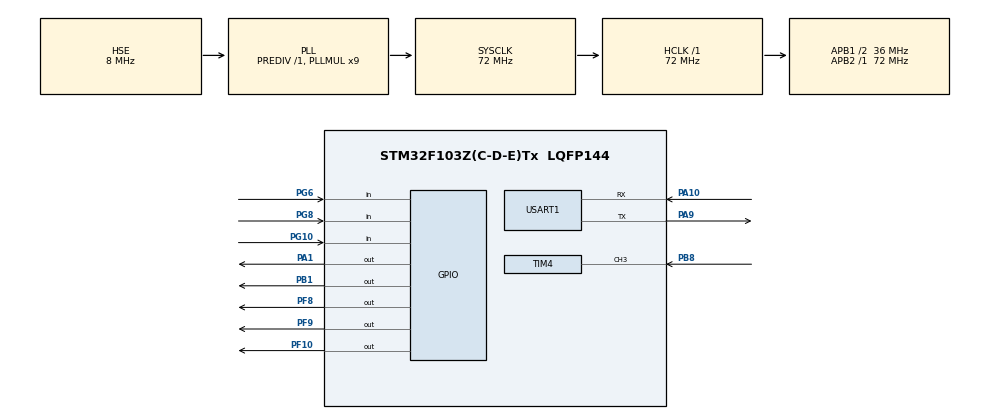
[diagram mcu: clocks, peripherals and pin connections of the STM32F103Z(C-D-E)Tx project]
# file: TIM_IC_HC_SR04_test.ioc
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Mcu.Family=STM32F1
Mcu.Name=STM32F103Z(C-D-E)Tx
Mcu.Package=LQFP144
NVIC.PriorityGroup=NVIC_PRIORITYGROUP_4
NVIC.TIM4_IRQn=true\:0\:0\:false\:false\:true\:true\:true\:true
NVIC.TIM6_IRQn=true\:0\:0\:false\:false\:true\:true\:true\:true
NVIC.TIM7_IRQn=true\:0\:0\:false\:false\:true\:true\:true\:true
OSC_IN.Mode=HSE-External-Oscillator
OSC_IN.Signal=RCC_OSC_IN
OSC_OUT.Mode=HSE-External-Oscillator
OSC_OUT.Signal=RCC_OSC_OUT
PA1.Signal=GPIO_Output
PA10.Mode=Asynchronous
PA10.Signal=USART1_RX
PA13.Mode=Serial_Wire
PA13.Signal=SYS_JTMS-SWDIO
PA14.Mode=Serial_Wire
PA14.Signal=SYS_JTCK-SWCLK
PA9.Mode=Asynchronous
PA9.Signal=USART1_TX
PB1.Signal=GPIO_Output
PB8.Signal=S_TIM4_CH3
PF10.PinState=GPIO_PIN_SET
PF10.Signal=GPIO_Output
PF8.PinState=GPIO_PIN_SET
PF8.Signal=GPIO_Output
PF9.PinState=GPIO_PIN_SET
PF9.Signal=GPIO_Output
PG10.Signal=GPIO_Input
PG6.Signal=GPIO_Input
PG8.Signal=GPIO_Input
ProjectManager.HeapSize=0x200
ProjectManager.StackSize=0x400
ProjectManager.TargetToolchain=MDK-ARM V5.32
RCC.AHBFreq_Value=72000000
RCC.APB1CLKDivider=RCC_HCLK_DIV2
RCC.APB1Freq_Value=36000000
RCC.APB1TimFreq_Value=72000000
RCC.APB2Freq_Value=72000000
RCC.APB2TimFreq_Value=72000000
RCC.HCLKFreq_Value=72000000
RCC.PLLMUL=RCC_PLL_MUL9
RCC.PLLSourceVirtual=RCC_PLLSOURCE_HSE
RCC.SYSCLKFreq_VALUE=72000000
RCC.SYSCLKSource=RCC_SYSCLKSOURCE_PLLCLK
RCC.USBFreq_Value=72000000
SH.S_TIM4_CH3.0=TIM4_CH3,Input_Capture3_from_TI3
TIM4.Channel-Input_Capture3_from_TI3=TIM_CHANNEL_3
TIM4.Channel-Input_Capture4_from_TI3_63=TIM_CHANNEL_4
TIM4.ICPolarity_CH4=TIM_INPUTCHANNELPOLARITY_FALLING
TIM4.Prescaler=71
TIM6.AutoReloadPreload=TIM_AUTORELOAD_PRELOAD_ENABLE
TIM6.Period=999
TIM6.Prescaler=71
TIM7.AutoReloadPreload=TIM_AUTORELOAD_PRELOAD_ENABLE
TIM7.Period=9
TIM7.Prescaler=71
USART1.Parity=PARITY_ODD
USART1.VirtualMode=VM_ASYNC
USART1.WordLength=WORDLENGTH_9B
VP_TIM4_VS_indirect_ch3.Mode=Input_Capture4_from_TI3_63
VP_TIM6_VS_ClockSourceINT.Mode=Enable_Timer
VP_TIM7_VS_ClockSourceINT.Mode=Enable_Timer
board=custom

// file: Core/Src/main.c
/* USER CODE BEGIN Header */
/**
  ******************************************************************************
  * @file           : main.c
  * @brief          : Main program body
  ******************************************************************************
  * @attention
  *
  * Copyright (c) 2026 STMicroelectronics.
  * All rights reserved.
  *
  * This software is licensed under terms that can be found in the LICENSE file
  * in the root directory of this software component.
  * If no LICENSE file comes with this software, it is provided AS-IS.
  *
  ******************************************************************************
  */
/* USER CODE END Header */
#include "main.h"

/* USER CODE BEGIN Includes */
#include "App_IC_Test.h"
/* USER CODE END Includes */

TIM_HandleTypeDef htim4;
TIM_HandleTypeDef htim6;
TIM_HandleTypeDef htim7;

UART_HandleTypeDef huart1;

void SystemClock_Config(void);
static void MX_GPIO_Init(void);
static void MX_TIM6_Init(void);
static void MX_TIM4_Init(void);
static void MX_TIM7_Init(void);
static void MX_USART1_UART_Init(void);

int main(void)
{

  /* MCU Configuration--------------------------------------------------------*/

  /* Reset of all peripherals, Initializes the Flash interface and the Systick. */
  HAL_Init();

  /* Configure the system clock */
  SystemClock_Config();

  /* Initialize all configured peripherals */
  MX_GPIO_Init();
  MX_TIM6_Init();
  MX_TIM4_Init();
  MX_TIM7_Init();
  MX_USART1_UART_Init();
  /* USER CODE BEGIN 2 */
  App_SetUp(&htim7, &htim6, &htim4, &huart1);
  /* USER CODE END 2 */

  /* Infinite loop */
  /* USER CODE BEGIN WHILE */
  while (1)
  {
    App_LoopOnce();
    /* USER CODE END WHILE */

  }
}

void SystemClock_Config(void)
{
  RCC_OscInitTypeDef RCC_OscInitStruct = {0};
  RCC_ClkInitTypeDef RCC_ClkInitStruct = {0};

  /** Initializes the RCC Oscillators according to the specified parameters
  * in the RCC_OscInitTypeDef structure.
  */
  RCC_OscInitStruct.OscillatorType = RCC_OSCILLATORTYPE_HSE;
  RCC_OscInitStruct.HSEState = RCC_HSE_ON;
  RCC_OscInitStruct.HSEPredivValue = RCC_HSE_PREDIV_DIV1;
  RCC_OscInitStruct.HSIState = RCC_HSI_ON;
  RCC_OscInitStruct.PLL.PLLState = RCC_PLL_ON;
  RCC_OscInitStruct.PLL.PLLSource = RCC_PLLSOURCE_HSE;
  RCC_OscInitStruct.PLL.PLLMUL = RCC_PLL_MUL9;
  if (HAL_RCC_OscConfig(&RCC_OscInitStruct) != HAL_OK)
  {
    Error_Handler();
  }

  /** Initializes the CPU, AHB and APB buses clocks
  */
  RCC_ClkInitStruct.ClockType = RCC_CLOCKTYPE_HCLK|RCC_CLOCKTYPE_SYSCLK
                              |RCC_CLOCKTYPE_PCLK1|RCC_CLOCKTYPE_PCLK2;
  RCC_ClkInitStruct.SYSCLKSource = RCC_SYSCLKSOURCE_PLLCLK;
  RCC_ClkInitStruct.AHBCLKDivider = RCC_SYSCLK_DIV1;
  RCC_ClkInitStruct.APB1CLKDivider = RCC_HCLK_DIV2;
  RCC_ClkInitStruct.APB2CLKDivider = RCC_HCLK_DIV1;

  if (HAL_RCC_ClockConfig(&RCC_ClkInitStruct, FLASH_LATENCY_2) != HAL_OK)
  {
    Error_Handler();
  }
}

static void MX_TIM4_Init(void)
{

  TIM_MasterConfigTypeDef sMasterConfig = {0};
  TIM_IC_InitTypeDef sConfigIC = {0};

  htim4.Instance = TIM4;
  htim4.Init.Prescaler = 71;
  htim4.Init.CounterMode = TIM_COUNTERMODE_UP;
  htim4.Init.Period = 65535;
  htim4.Init.ClockDivision = TIM_CLOCKDIVISION_DIV1;
  htim4.Init.AutoReloadPreload = TIM_AUTORELOAD_PRELOAD_DISABLE;
  if (HAL_TIM_IC_Init(&htim4) != HAL_OK)
  {
    Error_Handler();
  }
  sMasterConfig.MasterOutputTrigger = TIM_TRGO_RESET;
  sMasterConfig.MasterSlaveMode = TIM_MASTERSLAVEMODE_DISABLE;
  if (HAL_TIMEx_MasterConfigSynchronization(&htim4, &sMasterConfig) != HAL_OK)
  {
    Error_Handler();
  }
  sConfigIC.ICPolarity = TIM_INPUTCHANNELPOLARITY_RISING;
  sConfigIC.ICSelection = TIM_ICSELECTION_DIRECTTI;
  sConfigIC.ICPrescaler = TIM_ICPSC_DIV1;
  sConfigIC.ICFilter = 0;
  if (HAL_TIM_IC_ConfigChannel(&htim4, &sConfigIC, TIM_CHANNEL_3) != HAL_OK)
  {
    Error_Handler();
  }
  sConfigIC.ICPolarity = TIM_INPUTCHANNELPOLARITY_FALLING;
  sConfigIC.ICSelection = TIM_ICSELECTION_INDIRECTTI;
  if (HAL_TIM_IC_ConfigChannel(&htim4, &sConfigIC, TIM_CHANNEL_4) != HAL_OK)
  {
    Error_Handler();
  }

}

static void MX_TIM6_Init(void)
{

  TIM_MasterConfigTypeDef sMasterConfig = {0};

  htim6.Instance = TIM6;
  htim6.Init.Prescaler = 71;
  htim6.Init.CounterMode = TIM_COUNTERMODE_UP;
  htim6.Init.Period = 999;
  htim6.Init.AutoReloadPreload = TIM_AUTORELOAD_PRELOAD_ENABLE;
  if (HAL_TIM_Base_Init(&htim6) != HAL_OK)
  {
    Error_Handler();
  }
  sMasterConfig.MasterOutputTrigger = TIM_TRGO_RESET;
  sMasterConfig.MasterSlaveMode = TIM_MASTERSLAVEMODE_DISABLE;
  if (HAL_TIMEx_MasterConfigSynchronization(&htim6, &sMasterConfig) != HAL_OK)
  {
    Error_Handler();
  }

}

static void MX_TIM7_Init(void)
{

  TIM_MasterConfigTypeDef sMasterConfig = {0};

  htim7.Instance = TIM7;
  htim7.Init.Prescaler = 71;
  htim7.Init.CounterMode = TIM_COUNTERMODE_UP;
  htim7.Init.Period = 9;
  htim7.Init.AutoReloadPreload = TIM_AUTORELOAD_PRELOAD_ENABLE;
  if (HAL_TIM_Base_Init(&htim7) != HAL_OK)
  {
    Error_Handler();
  }
  sMasterConfig.MasterOutputTrigger = TIM_TRGO_RESET;
  sMasterConfig.MasterSlaveMode = TIM_MASTERSLAVEMODE_DISABLE;
  if (HAL_TIMEx_MasterConfigSynchronization(&htim7, &sMasterConfig) != HAL_OK)
  {
    Error_Handler();
  }

}

static void MX_USART1_UART_Init(void)
{

  huart1.Instance = USART1;
  huart1.Init.BaudRate = 115200;
  huart1.Init.WordLength = UART_WORDLENGTH_9B;
  huart1.Init.StopBits = UART_STOPBITS_1;
  huart1.Init.Parity = UART_PARITY_ODD;
  huart1.Init.Mode = UART_MODE_TX_RX;
  huart1.Init.HwFlowCtl = UART_HWCONTROL_NONE;
  huart1.Init.OverSampling = UART_OVERSAMPLING_16;
  if (HAL_UART_Init(&huart1) != HAL_OK)
  {
    Error_Handler();
  }

}

static void MX_GPIO_Init(void)
{
  GPIO_InitTypeDef GPIO_InitStruct = {0};

  /* GPIO Ports Clock Enable */
  __HAL_RCC_GPIOF_CLK_ENABLE();
  __HAL_RCC_GPIOA_CLK_ENABLE();
  __HAL_RCC_GPIOB_CLK_ENABLE();
  __HAL_RCC_GPIOG_CLK_ENABLE();

  /*Configure GPIO pin Output Level */
  HAL_GPIO_WritePin(GPIOF, GPIO_PIN_8|GPIO_PIN_9|GPIO_PIN_10, GPIO_PIN_SET);

  /*Configure GPIO pin Output Level */
  HAL_GPIO_WritePin(GPIOA, GPIO_PIN_1, GPIO_PIN_RESET);

  /*Configure GPIO pin Output Level */
  HAL_GPIO_WritePin(GPIOB, GPIO_PIN_1, GPIO_PIN_RESET);

  /*Configure GPIO pins : PF8 PF9 PF10 */
  GPIO_InitStruct.Pin = GPIO_PIN_8|GPIO_PIN_9|GPIO_PIN_10;
  GPIO_InitStruct.Mode = GPIO_MODE_OUTPUT_PP;
  GPIO_InitStruct.Pull = GPIO_NOPULL;
  GPIO_InitStruct.Speed = GPIO_SPEED_FREQ_LOW;
  HAL_GPIO_Init(GPIOF, &GPIO_InitStruct);

  /*Configure GPIO pin : PA1 */
  GPIO_InitStruct.Pin = GPIO_PIN_1;
  GPIO_InitStruct.Mode = GPIO_MODE_OUTPUT_PP;
  GPIO_InitStruct.Pull = GPIO_NOPULL;
  GPIO_InitStruct.Speed = GPIO_SPEED_FREQ_LOW;
  HAL_GPIO_Init(GPIOA, &GPIO_InitStruct);

  /*Configure GPIO pin : PB1 */
  GPIO_InitStruct.Pin = GPIO_PIN_1;
  GPIO_InitStruct.Mode = GPIO_MODE_OUTPUT_PP;
  GPIO_InitStruct.Pull = GPIO_NOPULL;
  GPIO_InitStruct.Speed = GPIO_SPEED_FREQ_LOW;
  HAL_GPIO_Init(GPIOB, &GPIO_InitStruct);

  /*Configure GPIO pins : PG6 PG8 PG10 */
  GPIO_InitStruct.Pin = GPIO_PIN_6|GPIO_PIN_8|GPIO_PIN_10;
  GPIO_InitStruct.Mode = GPIO_MODE_INPUT;
  GPIO_InitStruct.Pull = GPIO_NOPULL;
  HAL_GPIO_Init(GPIOG, &GPIO_InitStruct);

}

void Error_Handler(void)
{
  __disable_irq();
  while (1)
  {
  }
}
